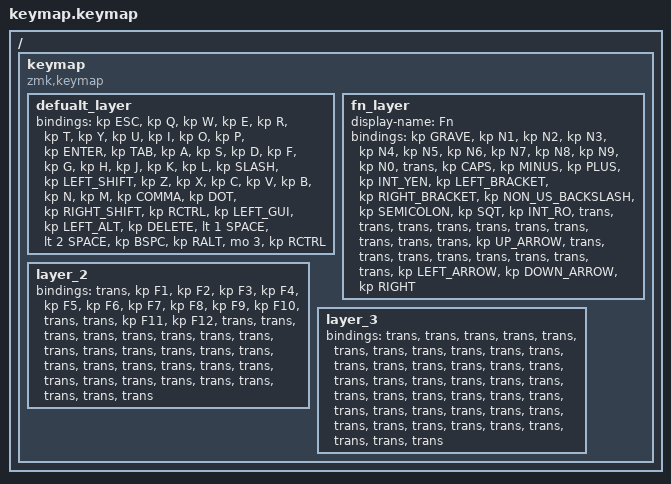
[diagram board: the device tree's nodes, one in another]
#include <behaviors.dtsi>
#include <dt-bindings/zmk/keys.h>

/ {
    keymap {
        compatible = "zmk,keymap";

        defualt_layer {
            bindings = <
&kp ESC  &kp Q  &kp W  &kp E  &kp R  &kp T  &kp Y  &kp U  &kp I  &kp O  &kp P  &kp ENTER  &kp TAB  &kp A  &kp S  &kp D  &kp F  &kp G  &kp H  &kp J  &kp K  &kp L  &kp SLASH  &kp LEFT_SHIFT  &kp Z  &kp X  &kp C  &kp V  &kp B  &kp N  &kp M  &kp COMMA  &kp DOT  &kp RIGHT_SHIFT  &kp RCTRL  &kp LEFT_GUI  &kp LEFT_ALT  &kp DELETE  &lt 1 SPACE  &lt 2 SPACE  &kp BSPC  &kp RALT  &mo 3  &kp RCTRL
            >;
        };

        fn_layer {
            display-name = "Fn";
            bindings = <
&kp GRAVE  &kp N1  &kp N2  &kp N3  &kp N4  &kp N5  &kp N6  &kp N7  &kp N8  &kp N9  &kp N0  &trans  &kp CAPS  &kp MINUS  &kp PLUS  &kp INT_YEN  &kp LEFT_BRACKET  &kp RIGHT_BRACKET  &kp NON_US_BACKSLASH  &kp SEMICOLON  &kp SQT  &kp INT_RO  &trans  &trans  &trans  &trans  &trans  &trans  &trans  &trans  &trans  &trans  &kp UP_ARROW  &trans  &trans  &trans  &trans  &trans  &trans  &trans  &trans  &kp LEFT_ARROW  &kp DOWN_ARROW  &kp RIGHT
            >;
        };

        layer_2 {
            bindings = <
&trans  &kp F1  &kp F2  &kp F3  &kp F4  &kp F5  &kp F6  &kp F7  &kp F8  &kp F9  &kp F10  &trans  &trans  &kp F11  &kp F12  &trans  &trans  &trans  &trans  &trans  &trans  &trans  &trans  &trans  &trans  &trans  &trans  &trans  &trans  &trans  &trans  &trans  &trans  &trans  &trans  &trans  &trans  &trans  &trans  &trans  &trans  &trans  &trans  &trans
            >;
        };

        layer_3 {
            bindings = <
&trans  &trans  &trans  &trans  &trans  &trans  &trans  &trans  &trans  &trans  &trans  &trans  &trans  &trans  &trans  &trans  &trans  &trans  &trans  &trans  &trans  &trans  &trans  &trans  &trans  &trans  &trans  &trans  &trans  &trans  &trans  &trans  &trans  &trans  &trans  &trans  &trans  &trans  &trans  &trans  &trans  &trans  &trans  &trans
            >;
        };
    };
};
